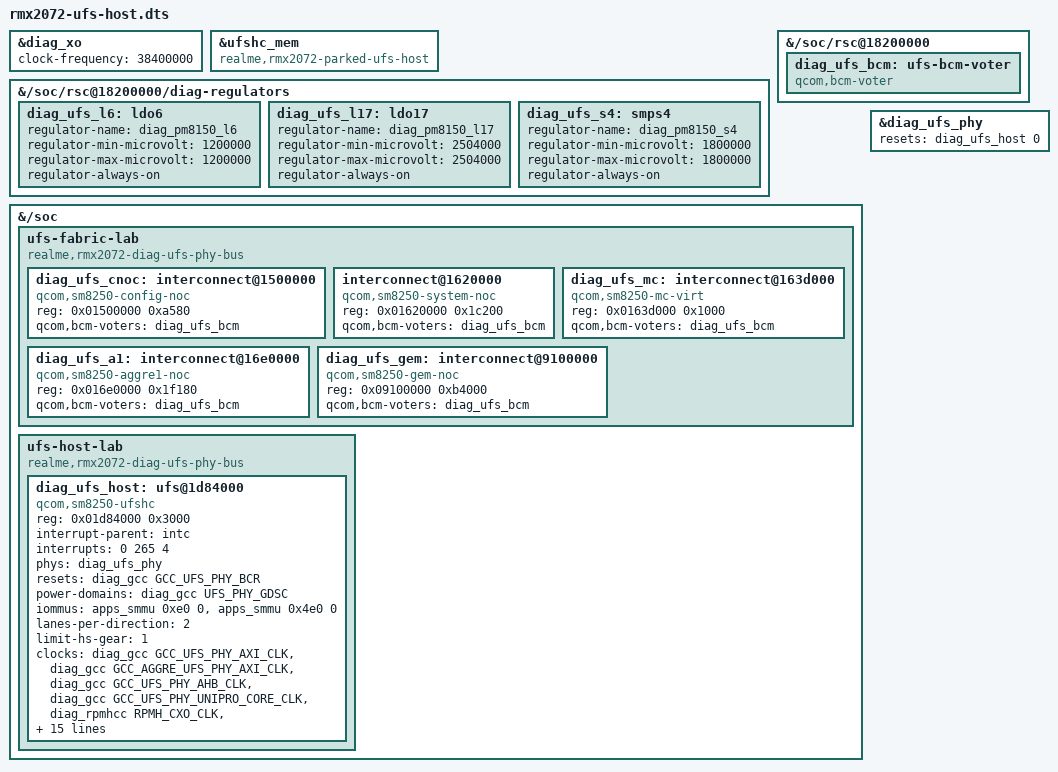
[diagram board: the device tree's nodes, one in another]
// SPDX-License-Identifier: GPL-2.0-only
// Stage the native UFS controller after ACM, PHY and fabric registration.
#define RMX2072_UFS_HOST_CONTROL
#include "rmx2072-ufs-phy.dts"
#include <dt-bindings/interconnect/qcom,sm8250.h>

// SM8250 RPMh divides the 38.4 MHz board oscillator to supply a 19.2 MHz CXO.
&diag_xo { clock-frequency = <38400000>; };

// OEM fragment 62 re-enables this target. Keep its symbols and supply fixups,
// but give the actual MMIO and IRQ to the staged native controller alone.
&ufshc_mem { compatible = "realme,rmx2072-parked-ufs-host"; };

&{/soc/rsc@18200000/diag-regulators} {
    diag_ufs_l6: ldo6 {
        regulator-name = "diag_pm8150_l6";
        regulator-min-microvolt = <1200000>;
        regulator-max-microvolt = <1200000>;
        regulator-always-on;
    };
    diag_ufs_l17: ldo17 {
        regulator-name = "diag_pm8150_l17";
        regulator-min-microvolt = <2504000>;
        regulator-max-microvolt = <2504000>;
        regulator-always-on;
    };
    diag_ufs_s4: smps4 {
        regulator-name = "diag_pm8150_s4";
        regulator-min-microvolt = <1800000>;
        regulator-max-microvolt = <1800000>;
        regulator-always-on;
    };
};

&{/soc/rsc@18200000} {
    diag_ufs_bcm: ufs-bcm-voter { compatible = "qcom,bcm-voter"; };
};

&{/soc} {
    #address-cells = <1>;
    #size-cells = <1>;
    ufs-fabric-lab {
        compatible = "realme,rmx2072-diag-ufs-phy-bus";
        #address-cells = <1>;
        #size-cells = <1>;
        ranges;
        diag_ufs_cnoc: interconnect@1500000 {
            compatible = "qcom,sm8250-config-noc";
            reg = <0x01500000 0xa580>;
            #interconnect-cells = <2>;
            qcom,bcm-voters = <&diag_ufs_bcm>;
        };
        interconnect@1620000 {
            compatible = "qcom,sm8250-system-noc";
            reg = <0x01620000 0x1c200>;
            #interconnect-cells = <2>;
            qcom,bcm-voters = <&diag_ufs_bcm>;
        };
        diag_ufs_mc: interconnect@163d000 {
            compatible = "qcom,sm8250-mc-virt";
            reg = <0x0163d000 0x1000>;
            #interconnect-cells = <2>;
            qcom,bcm-voters = <&diag_ufs_bcm>;
        };
        diag_ufs_a1: interconnect@16e0000 {
            compatible = "qcom,sm8250-aggre1-noc";
            reg = <0x016e0000 0x1f180>;
            #interconnect-cells = <2>;
            qcom,bcm-voters = <&diag_ufs_bcm>;
        };
        diag_ufs_gem: interconnect@9100000 {
            compatible = "qcom,sm8250-gem-noc";
            reg = <0x09100000 0xb4000>;
            #interconnect-cells = <2>;
            qcom,bcm-voters = <&diag_ufs_bcm>;
        };
    };

    ufs-host-lab {
        compatible = "realme,rmx2072-diag-ufs-phy-bus";
        #address-cells = <1>;
        #size-cells = <1>;
        ranges;
        diag_ufs_host: ufs@1d84000 {
            compatible = "qcom,sm8250-ufshc", "qcom,ufshc", "jedec,ufs-2.0";
            reg = <0x01d84000 0x3000>;
            interrupt-parent = <&intc>;
            interrupts = <0 265 4>;
            phys = <&diag_ufs_phy>;
            phy-names = "ufsphy";
            #reset-cells = <1>;
            resets = <&diag_gcc GCC_UFS_PHY_BCR>;
            reset-names = "rst";
            power-domains = <&diag_gcc UFS_PHY_GDSC>;
            iommus = <&apps_smmu 0xe0 0>, <&apps_smmu 0x4e0 0>;
            lanes-per-direction = <2>;
            // G3 initially reaches ACTIVE but generates repeated UIC errors.
            limit-hs-gear = <1>;
            clock-names = "core_clk", "bus_aggr_clk", "iface_clk", "core_clk_unipro",
                          "ref_clk", "tx_lane0_sync_clk", "rx_lane0_sync_clk", "rx_lane1_sync_clk";
            clocks = <&diag_gcc GCC_UFS_PHY_AXI_CLK>, <&diag_gcc GCC_AGGRE_UFS_PHY_AXI_CLK>,
                     <&diag_gcc GCC_UFS_PHY_AHB_CLK>, <&diag_gcc GCC_UFS_PHY_UNIPRO_CORE_CLK>,
                     <&diag_rpmhcc RPMH_CXO_CLK>, <&diag_gcc GCC_UFS_PHY_TX_SYMBOL_0_CLK>,
                     <&diag_gcc GCC_UFS_PHY_RX_SYMBOL_0_CLK>, <&diag_gcc GCC_UFS_PHY_RX_SYMBOL_1_CLK>;
            // Single low SM8250 rate for the bring-up profile.
            freq-table-hz = <37500000 37500000>, <0 0>, <0 0>, <37500000 37500000>,
                            <0 0>, <0 0>, <0 0>, <0 0>;
            interconnects = <&diag_ufs_a1 MASTER_UFS_MEM 0 &diag_ufs_mc SLAVE_EBI_CH0 0>,
                            <&diag_ufs_gem MASTER_AMPSS_M0 0 &diag_ufs_cnoc SLAVE_UFS_MEM_CFG 0>;
            interconnect-names = "ufs-ddr", "cpu-ufs";
            vcc-supply = <&diag_ufs_l17>;
            vccq-supply = <&diag_ufs_l6>;
            vccq2-supply = <&diag_ufs_s4>;
            vcc-max-microamp = <800000>;
            vccq-max-microamp = <800000>;
            vccq2-max-microamp = <800000>;
        };
    };
};

&diag_ufs_phy {
    resets = <&diag_ufs_host 0>;
    reset-names = "ufsphy";
};
